# STM32H757_CM7 register map
File version: 1.3
CPU: CM7 r0p1, little endian, MPU, FPU, 4 interrupt priority bits
Registers are 32-bit, read-write, reset 0x0 unless marked. A register's access mark holds for its fields unless they carry their own. Offsets are from the block's base; [hi:lo] are bit positions; {n}, {i} and the like mark numbered series; 'fields as' and 'values as' point back to an identical list.

## COMP1
Base 0x58003800
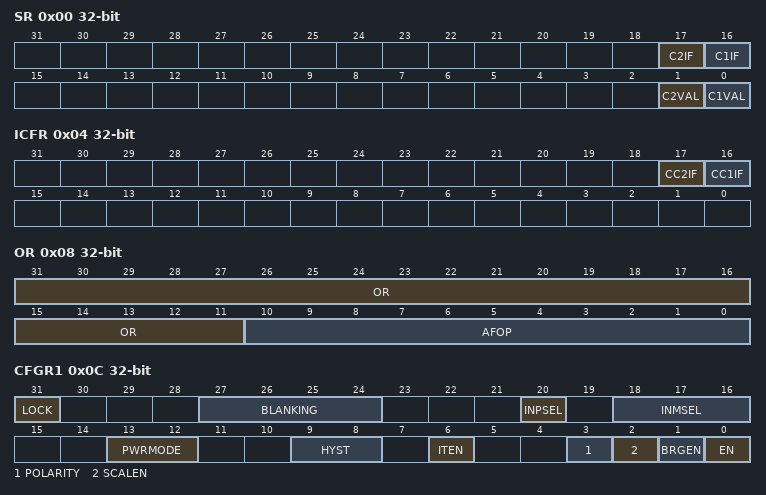
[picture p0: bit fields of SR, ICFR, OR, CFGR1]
0x00 SR ro — Comparator status register
  [17] C2IF — COMP channel 2 Interrupt Flag
  [16] C1IF — COMP channel 1 Interrupt Flag
  [1] C2VAL — COMP channel 2 output status bit
  [0] C1VAL — COMP channel 1 output status bit
0x04 ICFR wo — Comparator interrupt clear flag register
  [17] CC2IF — Clear COMP channel 2 Interrupt Flag
  [16] CC1IF — Clear COMP channel 1 Interrupt Flag
0x08 OR — Comparator option register
  [31:11] OR — Option Register
  [10:0] AFOP — Selection of source for alternate function of output ports
0x0C CFGR1 — Comparator configuration register 1
  [31] LOCK — Lock bit
  [27:24] BLANKING — COMP channel 1 blanking source selection bits
  [20] INPSEL — COMP channel 1 non-inverting input selection bit
  [18:16] INMSEL — COMP channel 1 inverting input selection field
  [13:12] PWRMODE — Power Mode of the COMP channel 1
  [9:8] HYST — COMP channel 1 hysteresis selection bits
  [6] ITEN — COMP channel 1 interrupt enable
  [3] POLARITY — COMP channel 1 polarity selection bit
  [2] SCALEN — Voltage scaler enable bit
  [1] BRGEN — Scaler bridge enable
  [0] EN — COMP channel 1 enable bit
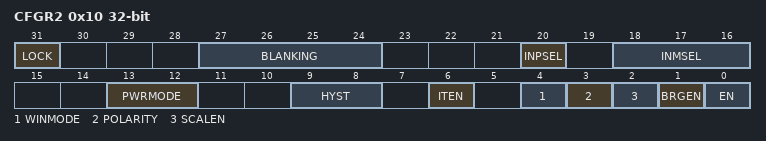
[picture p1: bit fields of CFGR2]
0x10 CFGR2 — Comparator configuration register 2
  [31] LOCK — Lock bit
  [27:24] BLANKING — COMP channel 1 blanking source selection bits
  [20] INPSEL — COMP channel 1 non-inverting input selection bit
  [18:16] INMSEL — COMP channel 1 inverting input selection field
  [13:12] PWRMODE — Power Mode of the COMP channel 1
  [9:8] HYST — COMP channel 1 hysteresis selection bits
  [6] ITEN — COMP channel 1 interrupt enable
  [4] WINMODE — Window comparator mode selection bit
  [3] POLARITY — COMP channel 1 polarity selection bit
  [2] SCALEN — Voltage scaler enable bit
  [1] BRGEN — Scaler bridge enable
  [0] EN — COMP channel 1 enable bit

## HSEM
Base 0x58026400
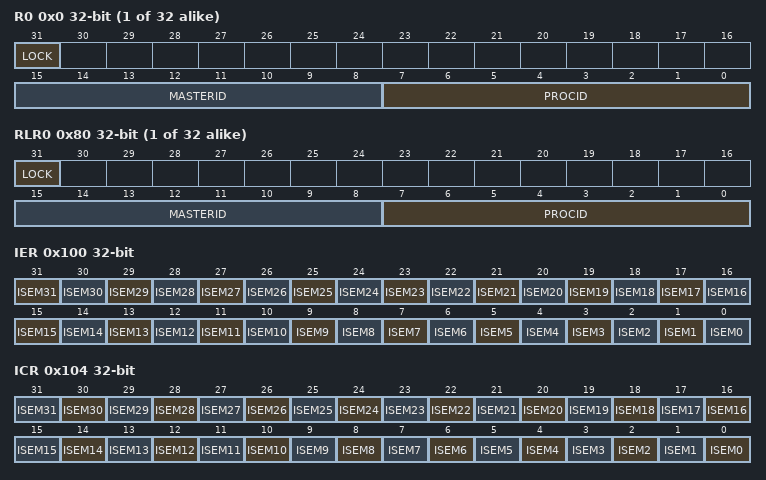
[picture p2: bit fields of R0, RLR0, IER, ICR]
{0x0+4i} R{i} (i=0..31) — HSEM register HSEM_R0 HSEM_R31
  [31] LOCK — Lock indication
  [15:8] MASTERID — Semaphore MasterID
  [7:0] PROCID — Semaphore ProcessID
{0x80+4i} RLR{i} ro (i=0..31) — HSEM Read lock register
  fields as R0
0x100 IER — HSEM Interrupt enable register
  [31] ISEM31 — Interrupt(N) semaphore n enable bit.
  [n] ISEM{n} (n=0..30) — Interrupt semaphore n enable bit
0x104 ICR ro — HSEM Interrupt clear register
  [n] ISEM{n} (n=0..31) — Interrupt(N) semaphore n clear bit
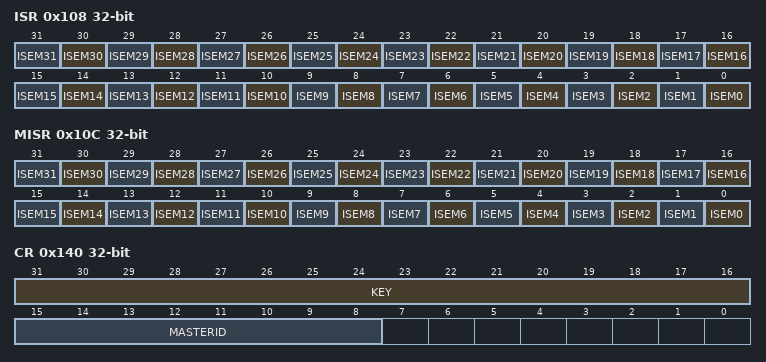
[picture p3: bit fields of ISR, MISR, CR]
0x108 ISR ro — HSEM Interrupt status register
  [n] ISEM{n} (n=0..31) — Interrupt(N) semaphore n status bit before enable (mask)
0x10C MISR ro — HSEM Masked interrupt status register
  [n] ISEM{n} (n=0..31) — masked interrupt(N) semaphore n status bit after enable (mask)
0x140 CR — HSEM Clear register
  [31:16] KEY — Semaphore clear Key
  [15:8] MASTERID — MasterID of semaphores to be cleared
0x144 KEYR — HSEM Interrupt clear register
  [31:16] KEY — Semaphore Clear Key

## RNG
Base 0x48021800
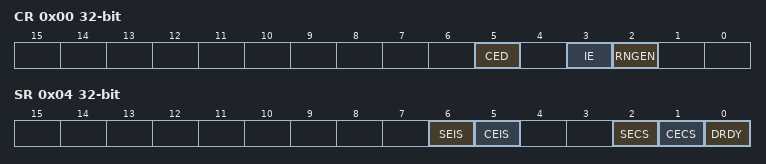
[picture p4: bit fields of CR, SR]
0x00 CR — RNG control register
  [5] CED — Clock error detection Note: The clock error detection can be used only when ck_rc48 or ck_pll1_q (ck_pll1_q = 48MHz) source is selected otherwise, CED bit must be equal to 1. The clock error detection cannot be enabled nor disabled on the fly when RNG peripheral is enabled, to enable or disable CED the RNG must be disabled.
    0=Enabled (Clock error detection is enabled); 1=Disabled (Clock error detection is disabled)
  [3] IE — Interrupt enable
    0=Disabled (RNG interrupt is disabled); 1=Enabled (RNG interrupt is enabled)
  [2] RNGEN — Random number generator enable
    0=Disabled (Random number generator is disabled); 1=Enabled (Random number generator is enabled)
0x04 SR access per field — RNG status register
  [6] SEIS rw — Seed error interrupt status This bit is set at the same time as SECS. It is cleared by writing it to 0. ** More than 64 consecutive bits at the same value (0 or 1) ** More than 32 consecutive alternances of 0 and 1 (0101010101...01) An interrupt is pending if IE = 1 in the RNG_CR register.
  [5] CEIS rw — Clock error interrupt status This bit is set at the same time as CECS. It is cleared by writing it to 0. An interrupt is pending if IE = 1 in the RNG_CR register. Note: This bit is meaningless if CED (Clock error detection) bit in RNG_CR is equal to 1.
  [2] SECS ro — Seed error current status ** More than 64 consecutive bits at the same value (0 or 1) ** More than 32 consecutive alternances of 0 and 1 (0101010101...01)
  [1] CECS ro — Clock error current status Note: This bit is meaningless if CED (Clock error detection) bit in RNG_CR is equal to 1.
  [0] DRDY ro — Data ready Note: If IE=1 in RNG_CR, an interrupt is generated when DRDY=1. It can rise when the peripheral is disabled. When the output buffer becomes empty (after reading RNG_DR), this bit returns to 0 until a new random value is generated.
0x08 DR ro — The RNG_DR register is a read-only register that delivers a 32-bit random value when read. The content of this register is valid when DRDY= 1, even if RNGEN=0.
  [31:0] RNDATA — Random data 32-bit random data which are valid when DRDY=1.
